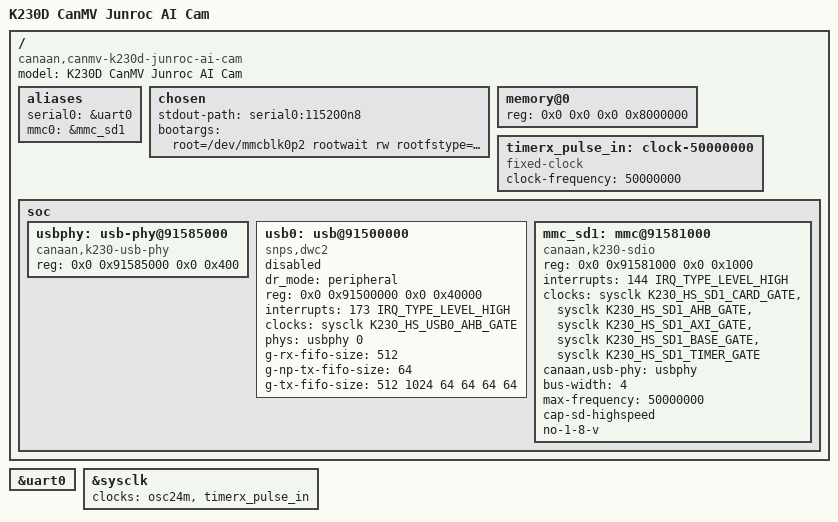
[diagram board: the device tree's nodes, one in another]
// SPDX-License-Identifier: GPL-2.0 OR MIT
/*
 * CanMV K230D AI-CAM on mainline Linux. Mainline's k230.dtsi stops at the
 * UARTs (7.3.3 and 7.4-rc1), so the SD and USB controllers are added here,
 * for the mainline drivers (sdhci-of-dwcmshc, phy-k230-usb, dwc2), with the
 * addresses and interrupts of the K230 Linux SDK's k230.dtsi. No pinctrl
 * states: as with the SDK's k230d-canmv.dts, the kernel keeps the pins the
 * SDK's U-Boot set up.
 * Node set from the vendor's Linux patches for this board (Canaan
 * k230_linux_sdk fc6cc215, buildroot-overlay/linux): 0024-add-junroc-board.patch
 * (model, compatible, the UART0 debug console behind the CH342K bridge, SD on
 * SDIO1 as mmc_sd1, WiFi RTL8189FTV on SDIO0, USB0 OTG, 128 MB), with
 * 0036-...-swap-mmc0-mmc1-aliases.patch's SD-as-mmc1 superseded by 0024's own
 * alias block on this board (SD is mmc0 here, so root=/dev/mmcblk0p2).
 *
 * First image: UART0 console at 115200 (ttyS0, the bench's CH342K bridge) and
 * the SD card (SDIO1) only. The vendor's stdout is UART2 (ttyS2): not used here.
 * Known from the vendor dts, NOT enabled in this image:
 *   - WiFi RTL8189FTV on SDIO0 (mmc_sd0, no-1-8-v): needs its firmware and
 *     the SDIO pins; the vendor's 0024 sets status okay.
 *   - camera GC2093 on I2C4 (vendor 0026/0031): MIPI RX1, MCLK1 on IO13
 *     (cam2_mclk_pins), reset GPIO10 (csi reset-gpios), CSI0/CSI1 disabled.
 *   - touch on I2C3 (reset GPIO23, irq GPIO22); DSI panel TX0, reset GPIO24,
 *     backlight GPIO25.
 *   - USB0 (the vendor's dts says dr_mode "otg"; this node says "peripheral", as Atlas
 *     reads the board's use): present and disabled in this image.
 * The U-Boot pad table (K230D junroc, from the schematic) is in U-Boot's
 * device tree, not here; the kernel keeps the pins U-Boot set.
 *
 * Written from the vendor patches and the bindings, untested on board.
 */
#include "k230.dtsi"

/ {
	model = "K230D CanMV Junroc AI Cam";
	compatible = "canaan,canmv-k230d-junroc-ai-cam", "canaan,canmv-k230d", "canaan,kendryte-k230";

	aliases {
		serial0 = &uart0;
		mmc0 = &mmc_sd1;
	};

	chosen {
		stdout-path = "serial0:115200n8";
		bootargs = "root=/dev/mmcblk0p2 rootwait rw rootfstype=ext4 console=ttyS0,115200 earlycon=sbi";
	};

	/* The K230D's in-package 128 MB. */
	memory@0 {
		device_type = "memory";
		reg = <0x0 0x0 0x0 0x8000000>;
	};

	timerx_pulse_in: clock-50000000 {
		compatible = "fixed-clock";
		#clock-cells = <0>;
		clock-frequency = <50000000>;
	};

	soc {
		usbphy: usb-phy@91585000 {
			compatible = "canaan,k230-usb-phy";
			reg = <0x0 0x91585000 0x0 0x400>;
			#phy-cells = <1>;
		};

		/* USB0: peripheral (a device, the gadget network) by the bench's decision,
		 * where the vendor's junroc dts says "otg". Disabled in the first image. */
		usb0: usb@91500000 {
			compatible = "snps,dwc2";
			status = "disabled";
			dr_mode = "peripheral";
			reg = <0x0 0x91500000 0x0 0x40000>;
			interrupts = <173 IRQ_TYPE_LEVEL_HIGH>;
			clocks = <&sysclk K230_HS_USB0_AHB_GATE>;
			clock-names = "otg";
			phys = <&usbphy 0>;
			phy-names = "usb2-phy";
			g-rx-fifo-size = <512>;
			g-np-tx-fifo-size = <64>;
			g-tx-fifo-size = <512 1024 64 64 64 64>;
		};

		/* The TF slot. */
		mmc_sd1: mmc@91581000 {
			compatible = "canaan,k230-sdio";
			status = "okay";
			reg = <0x0 0x91581000 0x0 0x1000>;
			interrupts = <144 IRQ_TYPE_LEVEL_HIGH>;
			clocks = <&sysclk K230_HS_SD1_CARD_GATE>,
				 <&sysclk K230_HS_SD1_AHB_GATE>,
				 <&sysclk K230_HS_SD1_AXI_GATE>,
				 <&sysclk K230_HS_SD1_BASE_GATE>,
				 <&sysclk K230_HS_SD1_TIMER_GATE>;
			clock-names = "core", "bus", "axi", "block", "timer";
			canaan,usb-phy = <&usbphy>;
			bus-width = <4>;
			max-frequency = <50000000>;
			cap-sd-highspeed;
			no-1-8-v;
		};
	};
};

/* UART0: the debug console (CH342K bridge). */
&uart0 {
	status = "okay";
};

&sysclk {
	clocks = <&osc24m>, <&timerx_pulse_in>;
	clock-names = "osc24m", "timer-pulse-in";
};
